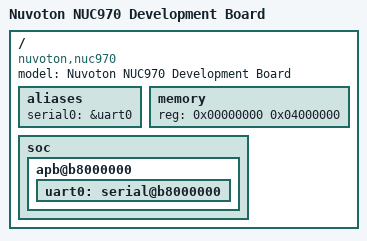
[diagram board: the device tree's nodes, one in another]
/*
 * Copyright 2016 Wan Zongshun <mcuos.com@gmail.com>
 *
 * The code contained herein is licensed under the GNU General Public
 * License. You may obtain a copy of the GNU General Public License
 * Version 2 or later at the following locations:
 *
 * http://www.opensource.org/licenses/gpl-license.html
 * http://www.gnu.org/copyleft/gpl.html
 */

/dts-v1/;
#include "nuc970.dtsi"

/ {
	model = "Nuvoton NUC970 Development Board";
	compatible = "nuvoton,nuc970";

	aliases {
		serial0 = &uart0;
	};

	memory {
		reg = <0x00000000 0x04000000>;
	};

	soc {
		apb@b8000000 {
			uart0: serial@b8000000 {
				status = "okay";
			};
		};
	};
};
